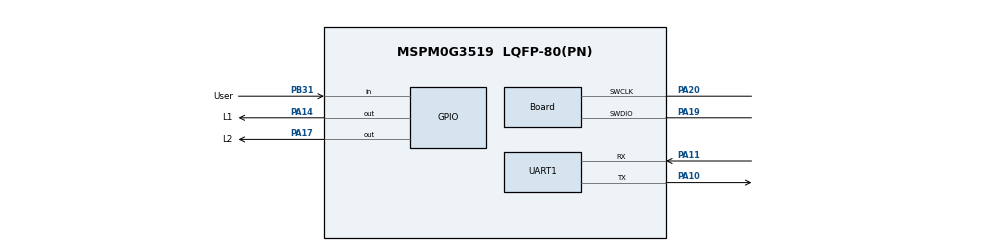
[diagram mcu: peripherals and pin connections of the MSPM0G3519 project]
/**
 * These arguments were used when this file was generated. They will be automatically applied on subsequent loads
 * via the GUI or CLI. Run CLI with '--help' for additional information on how to override these arguments.
 * @cliArgs --device "MSPM0G351X" --part "Default" --package "LQFP-80(PN)" --product "mspm0_sdk@2.10.00.04"
 * @v2CliArgs --device "MSPM0G3519" --package "LQFP-80(PN)" --product "mspm0_sdk@2.10.00.04"
 * @versions {"tool":"1.25.0+4268"}
 */

/**
 * Import the modules used in this configuration.
 */
const GPIO   = scripting.addModule("/ti/driverlib/GPIO", {}, false);
const GPIO1  = GPIO.addInstance();
const GPIO2  = GPIO.addInstance();
const SYSCTL = scripting.addModule("/ti/driverlib/SYSCTL");
const UART   = scripting.addModule("/ti/driverlib/UART", {}, false);
const UART1  = UART.addInstance();

/**
 * Write custom configuration values to the imported modules.
 */
GPIO1.$name                              = "LED";
GPIO1.associatedPins.create(2);
GPIO1.associatedPins[0].$name            = "L2";
GPIO1.associatedPins[0].internalResistor = "PULL_UP";
GPIO1.associatedPins[0].pin.$assign      = "PA17";
GPIO1.associatedPins[1].$name            = "L1";
GPIO1.associatedPins[1].internalResistor = "PULL_UP";
GPIO1.associatedPins[1].pin.$assign      = "PA14";

const Board                       = scripting.addModule("/ti/driverlib/Board", {}, false);
Board.peripheral.$assign          = "DEBUGSS";
Board.peripheral.swclkPin.$assign = "PA20";
Board.peripheral.swdioPin.$assign = "PA19";

GPIO2.$name                              = "Key";
GPIO2.associatedPins[0].$name            = "User";
GPIO2.associatedPins[0].direction        = "INPUT";
GPIO2.associatedPins[0].internalResistor = "PULL_UP";
GPIO2.associatedPins[0].pin.$assign      = "PB31";

SYSCTL.forceDefaultClkConfig = true;
SYSCTL.clockTreeEn           = true;

UART1.$name                    = "UART_0";
UART1.enabledInterrupts        = ["RX"];
UART1.peripheral.rxPin.$assign = "PA11";
UART1.peripheral.txPin.$assign = "PA10";
UART1.txPinConfig.$name        = "ti_driverlib_gpio_GPIOPinGeneric0";
UART1.rxPinConfig.$name        = "ti_driverlib_gpio_GPIOPinGeneric1";

const ProjectConfig              = scripting.addModule("/ti/project_config/ProjectConfig", {}, false);
ProjectConfig.migrationCondition = true;

/**
 * Pinmux solution for unlocked pins/peripherals. This ensures that minor changes to the automatic solver in a future
 * version of the tool will not impact the pinmux you originally saw.  These lines can be completely deleted in order to
 * re-solve from scratch.
 */
UART1.peripheral.$suggestSolution = "UART0";
